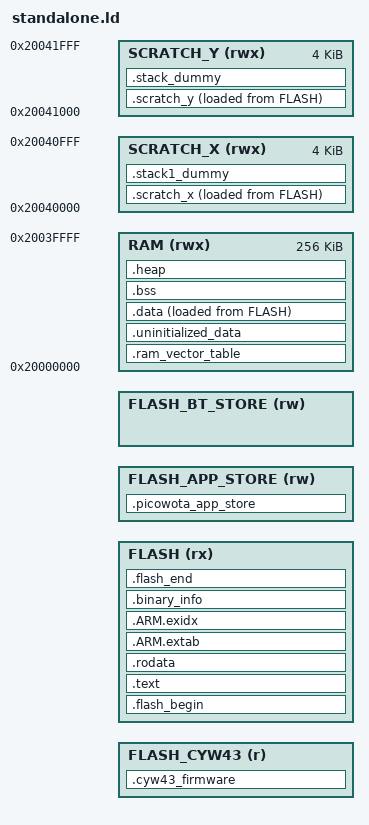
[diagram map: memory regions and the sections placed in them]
/* Based on GCC ARM embedded samples.
   Defines the following symbols for use by code:
    __exidx_start
    __exidx_end
    __etext
    __data_start__
    __preinit_array_start
    __preinit_array_end
    __init_array_start
    __init_array_end
    __fini_array_start
    __fini_array_end
    __data_end__
    __bss_start__
    __bss_end__
    __end__
    end
    __HeapLimit
    __StackLimit
    __StackTop
    __stack (== StackTop)
*/

flash_len           = 2048k;
app_header_len      = 4k;
cyw43_offset        = bootloader_len;
app_header_offset   = cyw43_offset      + cyw43_len;
app_image_offset    = app_header_offset + app_header_len;
app_image_len       = flash_len - app_image_offset - app_store_len - bt_store_len;
app_store_offset    = app_image_offset  + app_image_len;
bt_store_offset     = app_store_offset  + bt_store_len;

ASSERT(cyw43_len        % 4096 == 0, "`cyw43_len` is not 4 KiB aligned")
ASSERT(bootloader_len   % 4096 == 0, "`bootloader_len` is not 4 KiB aligned")
ASSERT(app_store_len    % 4096 == 0, "`app_store_len` is not 4 KiB aligned")
ASSERT(bt_store_len     % 4096 == 0, "`bt_store_len` is not 4 KiB aligned")

MEMORY
{
    FLASH_CYW43(r)      : ORIGIN = 0x10000000 + cyw43_offset        , LENGTH = cyw43_len
    FLASH(rx)           : ORIGIN = 0x10000000 + app_image_offset    , LENGTH = app_image_len
    FLASH_APP_STORE(rw) : ORIGIN = 0x10000000 + app_store_offset    , LENGTH = app_store_len
    FLASH_BT_STORE(rw)  : ORIGIN = 0x10000000 + bt_store_offset     , LENGTH = bt_store_len
    RAM(rwx)            : ORIGIN = 0x20000000, LENGTH = 256k
    SCRATCH_X(rwx)      : ORIGIN = 0x20040000, LENGTH = 4k
    SCRATCH_Y(rwx)      : ORIGIN = 0x20041000, LENGTH = 4k
}

ENTRY(_entry_point)

SECTIONS
{
    .cyw43_firmware : {
        . = ALIGN(4);
        KEEP (*(SORT_BY_ALIGNMENT(SORT_BY_NAME(.cyw43_firmware*))))
        . = ALIGN(4);
    } > FLASH_CYW43

    .picowota_app_store : {
        . = ALIGN(4k);
        PICOWOTA_APP_STORE = .;
    } > FLASH_APP_STORE

    .flash_begin : {
        __flash_binary_start = .;
    } > FLASH

    /* boot2 would normally go here, but we don't want it */

    .text : {
        __logical_binary_start = .;
        KEEP (*(.vectors))
        KEEP (*(.binary_info_header))
        __binary_info_header_end = .;
        KEEP (*(.reset))
        /* TODO revisit this now memset/memcpy/float in ROM */
        /* bit of a hack right now to exclude all floating point and time critical (e.g. memset, memcpy) code from
         * FLASH ... we will include any thing excluded here in .data below by default */
        *(.init)
        *(EXCLUDE_FILE(*libgcc.a: *libc.a:*lib_a-mem*.o *libm.a:) .text*)
        *(.fini)
        /* Pull all c'tors into .text */
        *crtbegin.o(.ctors)
        *crtbegin?.o(.ctors)
        *(EXCLUDE_FILE(*crtend?.o *crtend.o) .ctors)
        *(SORT(.ctors.*))
        *(.ctors)
        /* Followed by destructors */
        *crtbegin.o(.dtors)
        *crtbegin?.o(.dtors)
        *(EXCLUDE_FILE(*crtend?.o *crtend.o) .dtors)
        *(SORT(.dtors.*))
        *(.dtors)

        *(.eh_frame*)
        . = ALIGN(4);
    } > FLASH

    .rodata : {
        *(EXCLUDE_FILE(*libgcc.a: *libc.a:*lib_a-mem*.o *libm.a:) .rodata*)
        . = ALIGN(4);
        *(SORT_BY_ALIGNMENT(SORT_BY_NAME(.flashdata*)))
        . = ALIGN(4);
    } > FLASH

    .ARM.extab :
    {
        *(.ARM.extab* .gnu.linkonce.armextab.*)
    } > FLASH

    __exidx_start = .;
    .ARM.exidx :
    {
        *(.ARM.exidx* .gnu.linkonce.armexidx.*)
    } > FLASH
    __exidx_end = .;

    /* Machine inspectable binary information */
    . = ALIGN(4);
    __binary_info_start = .;
    .binary_info :
    {
        KEEP(*(.binary_info.keep.*))
        *(.binary_info.*)
    } > FLASH
    __binary_info_end = .;
    . = ALIGN(4);

    /* End of .text-like segments */
    __etext = .;

    .ram_vector_table (NOLOAD): {
        *(.ram_vector_table)
    } > RAM

    .uninitialized_data (NOLOAD): {
        . = ALIGN(4);
        *(.uninitialized_data*)
    } > RAM

    .data : {
        __data_start__ = .;
        *(vtable)

        *(.time_critical*)

        /* remaining .text and .rodata; i.e. stuff we exclude above because we want it in RAM */
        *(.text*)
        . = ALIGN(4);
        *(.rodata*)
        . = ALIGN(4);

        *(.data*)

        . = ALIGN(4);
        *(.after_data.*)
        . = ALIGN(4);
        /* preinit data */
        PROVIDE_HIDDEN (__mutex_array_start = .);
        KEEP(*(SORT(.mutex_array.*)))
        KEEP(*(.mutex_array))
        PROVIDE_HIDDEN (__mutex_array_end = .);

        . = ALIGN(4);
        /* preinit data */
        PROVIDE_HIDDEN (__preinit_array_start = .);
        KEEP(*(SORT(.preinit_array.*)))
        KEEP(*(.preinit_array))
        PROVIDE_HIDDEN (__preinit_array_end = .);

        . = ALIGN(4);
        /* init data */
        PROVIDE_HIDDEN (__init_array_start = .);
        KEEP(*(SORT(.init_array.*)))
        KEEP(*(.init_array))
        PROVIDE_HIDDEN (__init_array_end = .);

        . = ALIGN(4);
        /* finit data */
        PROVIDE_HIDDEN (__fini_array_start = .);
        *(SORT(.fini_array.*))
        *(.fini_array)
        PROVIDE_HIDDEN (__fini_array_end = .);

        *(.jcr)
        . = ALIGN(4);
        /* All data end */
        __data_end__ = .;
    } > RAM AT> FLASH

    /* Start and end symbols must be word-aligned */
    .scratch_x : {
        __scratch_x_start__ = .;
        *(.scratch_x.*)
        . = ALIGN(4);
        __scratch_x_end__ = .;
    } > SCRATCH_X AT > FLASH
    __scratch_x_source__ = LOADADDR(.scratch_x);

    .scratch_y : {
        __scratch_y_start__ = .;
        *(.scratch_y.*)
        . = ALIGN(4);
        __scratch_y_end__ = .;
    } > SCRATCH_Y AT > FLASH
    __scratch_y_source__ = LOADADDR(.scratch_y);

    .bss  : {
        . = ALIGN(4);
        __bss_start__ = .;
        *(SORT_BY_ALIGNMENT(SORT_BY_NAME(.bss*)))
        *(COMMON)
        . = ALIGN(4);
        __bss_end__ = .;
    } > RAM

    .heap (COPY):
    {
        __end__ = .;
        end = __end__;
        *(.heap*)
        __HeapLimit = .;
    } > RAM

    /* .stack*_dummy section doesn't contains any symbols. It is only
     * used for linker to calculate size of stack sections, and assign
     * values to stack symbols later
     *
     * stack1 section may be empty/missing if platform_launch_core1 is not used */

    /* by default we put core 0 stack at the end of scratch Y, so that if core 1
     * stack is not used then all of SCRATCH_X is free.
     */
    .stack1_dummy (COPY):
    {
        *(.stack1*)
    } > SCRATCH_X
    .stack_dummy (COPY):
    {
        *(.stack*)
    } > SCRATCH_Y

    .flash_end : {
        __flash_binary_end = .;
    } > FLASH

    PICOWOTA_APP_STORE_END = ORIGIN(FLASH_APP_STORE) + LENGTH(FLASH_APP_STORE);

    /* stack limit is poorly named, but historically is maximum heap ptr */
    __StackLimit = ORIGIN(RAM) + LENGTH(RAM);
    __StackOneTop = ORIGIN(SCRATCH_X) + LENGTH(SCRATCH_X);
    __StackTop = ORIGIN(SCRATCH_Y) + LENGTH(SCRATCH_Y);
    __StackOneBottom = __StackOneTop - SIZEOF(.stack1_dummy);
    __StackBottom = __StackTop - SIZEOF(.stack_dummy);
    PROVIDE(__stack = __StackTop);

    /* Check if data + heap + stack exceeds RAM limit */
    ASSERT(__StackLimit >= __HeapLimit, "region RAM overflowed")

    ASSERT( __binary_info_header_end - __logical_binary_start <= 256, "Binary info must be in first 256 bytes of the binary")
    /* todo assert on extra code */
}
